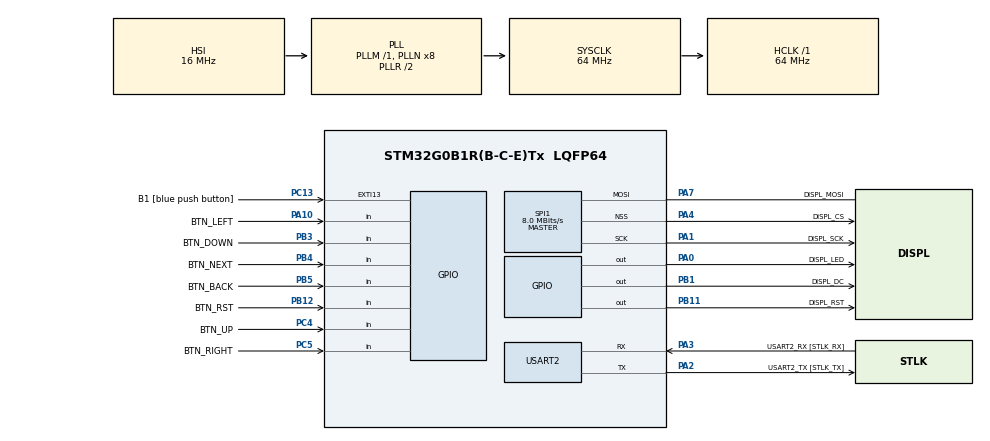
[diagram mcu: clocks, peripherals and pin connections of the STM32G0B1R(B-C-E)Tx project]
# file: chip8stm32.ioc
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Dma.Request0=SPI1_TX
Dma.SPI1_TX.0.Direction=DMA_MEMORY_TO_PERIPH
Dma.SPI1_TX.0.EventEnable=DISABLE
Dma.SPI1_TX.0.Instance=DMA1_Channel1
Dma.SPI1_TX.0.MemDataAlignment=DMA_MDATAALIGN_BYTE
Dma.SPI1_TX.0.MemInc=DMA_MINC_ENABLE
Dma.SPI1_TX.0.Mode=DMA_NORMAL
Dma.SPI1_TX.0.PeriphDataAlignment=DMA_PDATAALIGN_BYTE
Dma.SPI1_TX.0.PeriphInc=DMA_PINC_DISABLE
Dma.SPI1_TX.0.Polarity=HAL_DMAMUX_REQ_GEN_RISING
Dma.SPI1_TX.0.Priority=DMA_PRIORITY_LOW
Dma.SPI1_TX.0.RequestNumber=1
Dma.SPI1_TX.0.SignalID=NONE
Dma.SPI1_TX.0.SyncEnable=DISABLE
Dma.SPI1_TX.0.SyncPolarity=HAL_DMAMUX_SYNC_NO_EVENT
Dma.SPI1_TX.0.SyncRequestNumber=1
Dma.SPI1_TX.0.SyncSignalID=NONE
Mcu.Family=STM32G0
Mcu.Name=STM32G0B1R(B-C-E)Tx
Mcu.Package=LQFP64
Mcu.UserConstants=DEBOUNCE_COUNT,10000
NVIC.DMA1_Channel1_IRQn=true\:0\:0\:false\:false\:true\:false\:true\:true
NVIC.SPI1_IRQn=true\:0\:0\:false\:false\:true\:true\:true\:true
PA0.GPIO_Label=DISPL_LED
PA0.Signal=GPIO_Output
PA1.GPIO_Label=DISPL_SCK
PA1.Mode=Simplex_Bidirectional_Master
PA1.Signal=SPI1_SCK
PA10.GPIO_Label=BTN_LEFT
PA10.GPIO_PuPd=GPIO_PULLUP
PA10.Signal=GPIO_Input
PA13.GPIO_Label=TMS
PA13.Mode=Serial_Wire
PA13.Signal=SYS_SWDIO
PA14-BOOT0.GPIO_Label=TCK
PA14-BOOT0.Mode=Serial_Wire
PA14-BOOT0.Signal=SYS_SWCLK
PA2.GPIO_Label=USART2_TX [STLK_TX]
PA2.Mode=Asynchronous
PA2.Signal=USART2_TX
PA3.GPIO_Label=USART2_RX [STLK_RX]
PA3.Mode=Asynchronous
PA3.Signal=USART2_RX
PA4.GPIO_Label=DISPL_CS
PA4.Mode=NSS_Signal_Hard_Output
PA4.Signal=SPI1_NSS
PA7.GPIO_Label=DISPL_MOSI
PA7.Mode=Simplex_Bidirectional_Master
PA7.Signal=SPI1_MOSI
PB1.GPIO_Label=DISPL_DC
PB1.PinState=GPIO_PIN_RESET
PB1.Signal=GPIO_Output
PB11.GPIO_Label=DISPL_RST
PB11.Signal=GPIO_Output
PB12.GPIO_Label=BTN_RST
PB12.GPIO_PuPd=GPIO_PULLUP
PB12.Signal=GPIO_Input
PB3.GPIO_Label=BTN_DOWN
PB3.GPIO_PuPd=GPIO_PULLUP
PB3.Signal=GPIO_Input
PB4.GPIO_Label=BTN_NEXT
PB4.GPIO_PuPd=GPIO_PULLUP
PB4.Signal=GPIO_Input
PB5.GPIO_Label=BTN_BACK
PB5.GPIO_PuPd=GPIO_PULLUP
PB5.Signal=GPIO_Input
PC13.GPIO_Label=B1 [blue push button]
PC13.Signal=GPXTI13
PC14-OSC32_IN\ (PC14).Mode=LSE-External-Oscillator
PC14-OSC32_IN\ (PC14).Signal=RCC_OSC32_IN
PC15-OSC32_OUT\ (PC15).Mode=LSE-External-Oscillator
PC15-OSC32_OUT\ (PC15).Signal=RCC_OSC32_OUT
PC4.GPIO_Label=BTN_UP
PC4.GPIO_PuPd=GPIO_PULLUP
PC4.Signal=GPIO_Input
PC5.GPIO_Label=BTN_RIGHT
PC5.GPIO_PuPd=GPIO_PULLUP
PC5.Signal=GPIO_Input
PF0-OSC_IN\ (PF0).GPIO_Label=MCO
PF0-OSC_IN\ (PF0).Mode=HSE-External-Clock-Source
PF0-OSC_IN\ (PF0).Signal=RCC_OSC_IN
ProjectManager.HeapSize=0x200
ProjectManager.StackSize=0x400
ProjectManager.TargetToolchain=CMake
RCC.ADCFreq_Value=64000000
RCC.AHBFreq_Value=64000000
RCC.CortexFreq_Value=64000000
RCC.EXTERNAL_CLOCK_VALUE=12288000
RCC.HCLKFreq_Value=64000000
RCC.HSE_VALUE=8000000
RCC.HSI48_VALUE=48000000
RCC.HSI_VALUE=16000000
RCC.SYSCLKFreq_VALUE=64000000
RCC.SYSCLKSource=RCC_SYSCLKSOURCE_PLLCLK
RCC.USBFreq_Value=48000000
RCC.VCOOutputFreq_Value=128000000
SPI1.BaudRatePrescaler=SPI_BAUDRATEPRESCALER_8
SPI1.CalculateBaudRate=8.0 MBits/s
SPI1.DataSize=SPI_DATASIZE_8BIT
SPI1.Direction=SPI_DIRECTION_1LINE
SPI1.Mode=SPI_MODE_MASTER
SPI1.VirtualNSS=VM_NSSHARD
SPI1.VirtualType=VM_MASTER
USART2.VirtualMode-Asynchronous=VM_ASYNC
VP_SYS_VS_DBSignals.Mode=DisableDeadBatterySignals
board=NUCLEO-G0B1RE

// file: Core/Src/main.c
/* USER CODE BEGIN Header */
/**
  ******************************************************************************
  * @file           : main.c
  * @brief          : Main program body
  ******************************************************************************
  * @attention
  *
  * Copyright (c) 2026 STMicroelectronics.
  * All rights reserved.
  *
  * This software is licensed under terms that can be found in the LICENSE file
  * in the root directory of this software component.
  * If no LICENSE file comes with this software, it is provided AS-IS.
  *
  ******************************************************************************
  */
/* USER CODE END Header */
#include "main.h"
#include "stm32_hal_legacy.h"

/* USER CODE BEGIN Includes */
#include <stdbool.h>
/* USER CODE END Includes */

SPI_HandleTypeDef hspi1;
DMA_HandleTypeDef hdma_spi1_tx;

UART_HandleTypeDef huart2;

void SystemClock_Config(void);
static void MX_GPIO_Init(void);
static void MX_DMA_Init(void);
static void MX_SPI1_Init(void);
static void MX_USART2_UART_Init(void);

int main(void)
{

  /* MCU Configuration--------------------------------------------------------*/

  /* Reset of all peripherals, Initializes the Flash interface and the Systick. */
  HAL_Init();

  /* Configure the system clock */
  SystemClock_Config();

  /* Initialize all configured peripherals */
  MX_GPIO_Init();
  MX_DMA_Init();
  MX_SPI1_Init();
  MX_USART2_UART_Init();
  /* USER CODE BEGIN 2 */
  Displ_Init(Displ_Orientat_0);
  Displ_CLS(BLACK);
  Displ_BackLight('I');

  /* USER CODE END 2 */

  /* Infinite loop */
  /* USER CODE BEGIN WHILE */
  while (1)
  {
    main_emu();
    /* USER CODE END WHILE */

  }
}

void SystemClock_Config(void)
{
  RCC_OscInitTypeDef RCC_OscInitStruct = {0};
  RCC_ClkInitTypeDef RCC_ClkInitStruct = {0};

  /** Configure the main internal regulator output voltage
  */
  HAL_PWREx_ControlVoltageScaling(PWR_REGULATOR_VOLTAGE_SCALE1);

  /** Initializes the RCC Oscillators according to the specified parameters
  * in the RCC_OscInitTypeDef structure.
  */
  RCC_OscInitStruct.OscillatorType = RCC_OSCILLATORTYPE_HSI;
  RCC_OscInitStruct.HSIState = RCC_HSI_ON;
  RCC_OscInitStruct.HSIDiv = RCC_HSI_DIV1;
  RCC_OscInitStruct.HSICalibrationValue = RCC_HSICALIBRATION_DEFAULT;
  RCC_OscInitStruct.PLL.PLLState = RCC_PLL_ON;
  RCC_OscInitStruct.PLL.PLLSource = RCC_PLLSOURCE_HSI;
  RCC_OscInitStruct.PLL.PLLM = RCC_PLLM_DIV1;
  RCC_OscInitStruct.PLL.PLLN = 8;
  RCC_OscInitStruct.PLL.PLLP = RCC_PLLP_DIV2;
  RCC_OscInitStruct.PLL.PLLQ = RCC_PLLQ_DIV2;
  RCC_OscInitStruct.PLL.PLLR = RCC_PLLR_DIV2;
  if (HAL_RCC_OscConfig(&RCC_OscInitStruct) != HAL_OK)
  {
    Error_Handler();
  }

  /** Initializes the CPU, AHB and APB buses clocks
  */
  RCC_ClkInitStruct.ClockType = RCC_CLOCKTYPE_HCLK|RCC_CLOCKTYPE_SYSCLK
                              |RCC_CLOCKTYPE_PCLK1;
  RCC_ClkInitStruct.SYSCLKSource = RCC_SYSCLKSOURCE_PLLCLK;
  RCC_ClkInitStruct.AHBCLKDivider = RCC_SYSCLK_DIV1;
  RCC_ClkInitStruct.APB1CLKDivider = RCC_HCLK_DIV1;

  if (HAL_RCC_ClockConfig(&RCC_ClkInitStruct, FLASH_LATENCY_2) != HAL_OK)
  {
    Error_Handler();
  }
}

static void MX_SPI1_Init(void)
{

  /* SPI1 parameter configuration*/
  hspi1.Instance = SPI1;
  hspi1.Init.Mode = SPI_MODE_MASTER;
  hspi1.Init.Direction = SPI_DIRECTION_1LINE;
  hspi1.Init.DataSize = SPI_DATASIZE_8BIT;
  hspi1.Init.CLKPolarity = SPI_POLARITY_LOW;
  hspi1.Init.CLKPhase = SPI_PHASE_1EDGE;
  hspi1.Init.NSS = SPI_NSS_HARD_OUTPUT;
  hspi1.Init.BaudRatePrescaler = SPI_BAUDRATEPRESCALER_8;
  hspi1.Init.FirstBit = SPI_FIRSTBIT_MSB;
  hspi1.Init.TIMode = SPI_TIMODE_DISABLE;
  hspi1.Init.CRCCalculation = SPI_CRCCALCULATION_DISABLE;
  hspi1.Init.CRCPolynomial = 7;
  hspi1.Init.CRCLength = SPI_CRC_LENGTH_DATASIZE;
  hspi1.Init.NSSPMode = SPI_NSS_PULSE_ENABLE;
  if (HAL_SPI_Init(&hspi1) != HAL_OK)
  {
    Error_Handler();
  }

}

static void MX_USART2_UART_Init(void)
{

  huart2.Instance = USART2;
  huart2.Init.BaudRate = 115200;
  huart2.Init.WordLength = UART_WORDLENGTH_8B;
  huart2.Init.StopBits = UART_STOPBITS_1;
  huart2.Init.Parity = UART_PARITY_NONE;
  huart2.Init.Mode = UART_MODE_TX_RX;
  huart2.Init.HwFlowCtl = UART_HWCONTROL_NONE;
  huart2.Init.OverSampling = UART_OVERSAMPLING_16;
  huart2.Init.OneBitSampling = UART_ONE_BIT_SAMPLE_DISABLE;
  huart2.Init.ClockPrescaler = UART_PRESCALER_DIV1;
  huart2.AdvancedInit.AdvFeatureInit = UART_ADVFEATURE_NO_INIT;
  if (HAL_UART_Init(&huart2) != HAL_OK)
  {
    Error_Handler();
  }
  if (HAL_UARTEx_SetTxFifoThreshold(&huart2, UART_TXFIFO_THRESHOLD_1_8) != HAL_OK)
  {
    Error_Handler();
  }
  if (HAL_UARTEx_SetRxFifoThreshold(&huart2, UART_RXFIFO_THRESHOLD_1_8) != HAL_OK)
  {
    Error_Handler();
  }
  if (HAL_UARTEx_DisableFifoMode(&huart2) != HAL_OK)
  {
    Error_Handler();
  }

}

static void MX_DMA_Init(void)
{

  /* DMA controller clock enable */
  __HAL_RCC_DMA1_CLK_ENABLE();

  /* DMA interrupt init */
  /* DMA1_Channel1_IRQn interrupt configuration */
  HAL_NVIC_SetPriority(DMA1_Channel1_IRQn, 0, 0);
  HAL_NVIC_EnableIRQ(DMA1_Channel1_IRQn);

}

static void MX_GPIO_Init(void)
{
  GPIO_InitTypeDef GPIO_InitStruct = {0};

  /* GPIO Ports Clock Enable */
  __HAL_RCC_GPIOC_CLK_ENABLE();
  __HAL_RCC_GPIOF_CLK_ENABLE();
  __HAL_RCC_GPIOA_CLK_ENABLE();
  __HAL_RCC_GPIOB_CLK_ENABLE();

  /*Configure GPIO pin Output Level */
  HAL_GPIO_WritePin(DISPL_LED_GPIO_Port, DISPL_LED_Pin, GPIO_PIN_RESET);

  /*Configure GPIO pin Output Level */
  HAL_GPIO_WritePin(GPIOB, DISPL_DC_Pin|DISPL_RST_Pin, GPIO_PIN_RESET);

  /*Configure GPIO pin : B1_Pin */
  GPIO_InitStruct.Pin = B1_Pin;
  GPIO_InitStruct.Mode = GPIO_MODE_IT_RISING;
  GPIO_InitStruct.Pull = GPIO_NOPULL;
  HAL_GPIO_Init(B1_GPIO_Port, &GPIO_InitStruct);

  /*Configure GPIO pin : DISPL_LED_Pin */
  GPIO_InitStruct.Pin = DISPL_LED_Pin;
  GPIO_InitStruct.Mode = GPIO_MODE_OUTPUT_PP;
  GPIO_InitStruct.Pull = GPIO_NOPULL;
  GPIO_InitStruct.Speed = GPIO_SPEED_FREQ_LOW;
  HAL_GPIO_Init(DISPL_LED_GPIO_Port, &GPIO_InitStruct);

  /*Configure GPIO pins : BTN_UP_Pin BTN_RIGHT_Pin */
  GPIO_InitStruct.Pin = BTN_UP_Pin|BTN_RIGHT_Pin;
  GPIO_InitStruct.Mode = GPIO_MODE_INPUT;
  GPIO_InitStruct.Pull = GPIO_PULLUP;
  HAL_GPIO_Init(GPIOC, &GPIO_InitStruct);

  /*Configure GPIO pins : DISPL_DC_Pin DISPL_RST_Pin */
  GPIO_InitStruct.Pin = DISPL_DC_Pin|DISPL_RST_Pin;
  GPIO_InitStruct.Mode = GPIO_MODE_OUTPUT_PP;
  GPIO_InitStruct.Pull = GPIO_NOPULL;
  GPIO_InitStruct.Speed = GPIO_SPEED_FREQ_LOW;
  HAL_GPIO_Init(GPIOB, &GPIO_InitStruct);

  /*Configure GPIO pins : BTN_RST_Pin BTN_DOWN_Pin BTN_NEXT_Pin BTN_BACK_Pin */
  GPIO_InitStruct.Pin = BTN_RST_Pin|BTN_DOWN_Pin|BTN_NEXT_Pin|BTN_BACK_Pin;
  GPIO_InitStruct.Mode = GPIO_MODE_INPUT;
  GPIO_InitStruct.Pull = GPIO_PULLUP;
  HAL_GPIO_Init(GPIOB, &GPIO_InitStruct);

  /*Configure GPIO pin : BTN_LEFT_Pin */
  GPIO_InitStruct.Pin = BTN_LEFT_Pin;
  GPIO_InitStruct.Mode = GPIO_MODE_INPUT;
  GPIO_InitStruct.Pull = GPIO_PULLUP;
  HAL_GPIO_Init(BTN_LEFT_GPIO_Port, &GPIO_InitStruct);

}

void Error_Handler(void)
{
  __disable_irq();
  while (1)
  {
  }
}
